AUTOSAR XML (schema 4-0-3)
package /AUTOSAR_Dcm/ImplementationDataTypes
  42 x impl type:
    DataArrayType_SystemSupplierECUHardwareVersionNumber: category=ARRAY
      element DataArrayType: array-size=4, array-size-semantics=FIXED-SIZE, implementation-data-type=uint8
    Dcm_EcuStartModeType: category=VALUE, base-type=uint8, compu {0x00=DCM_COLD_START, 0x01=DCM_WARM_START}, range raw 0x00..0x01
    DataArrayType_VINDataIdentifier: category=ARRAY
      element DataArrayType: array-size=17, array-size-semantics=FIXED-SIZE, implementation-data-type=uint8
    Dcm_ProtocolType:
      category=VALUE
      base-type=uint8
      compu {0x00=DCM_OBD_ON_CAN, 0x01=DCM_OBD_ON_FLEXRAY, 0x02=DCM_OBD_ON_IP, 0x03=DCM_UDS_ON_CAN, 0x04=DCM_UDS_ON_FLEXRAY, 0x05=DCM_UDS_ON_IP, 0x06=DCM_ROE_ON_CAN, 0x07=DCM_ROE_ON_FLEXRAY, 0x08=DCM_ROE_ON_IP, 0x09=DCM_PERIODICTRANS_ON_CAN, 0x0A=DCM_PERIODICTRANS_ON_FLEXRAY, 0x0B=DCM_PERIODICTRANS_ON_IP, 0x0C=DCM_NO_ACTIVE_PROTOCOL, 0xF0=DCM_SUPPLIER_1, 0xF1=DCM_SUPPLIER_2, 0xF2=DCM_SUPPLIER_3, 0xF3=DCM_SUPPLIER_4, 0xF4=DCM_SUPPLIER_5, 0xF5=DCM_SUPPLIER_6, 0xF6=DCM_SUPPLIER_7, 0xF7=DCM_SUPPLIER_8, 0xF8=DCM_SUPPLIER_9, 0xF9=DCM_SUPPLIER_10, 0xFA=DCM_SUPPLIER_11, 0xFB=DCM_SUPPLIER_12, 0xFC=DCM_SUPPLIER_13, 0xFD=DCM_SUPPLIER_14, 0xFE=DCM_SUPPLIER_15}
      range raw 0x00..0xFE
    Dcm_OpStatusType: category=VALUE, base-type=uint8, compu {0x00=DCM_INITIAL, 0x01=DCM_PENDING, 0x02=DCM_CANCEL, 0x03=DCM_FORCE_RCRRP_OK}, range raw 0x00..0x03
    Dcm_SecLevelType: category=VALUE, base-type=uint8, compu {0x00=DCM_SEC_LEV_LOCKED, 0x01=DCM_SEC_LEV_L1, 0x09=DCM_SEC_LEV_L9, 0x21=DCM_SEC_LEV_L21, 0xFF=DCM_SEC_LEV_ALL}, range raw 0x00..0xFF
    Dcm_MsgItemType: category=VALUE, base-type=uint8, range raw 0..255
    Dcm_ReturnReadMemoryType: category=VALUE, base-type=uint8, compu {0x02=DCM_READ_FAILED, 0x03=DCM_READ_FORCE_RCRRP, 0x00=DCM_READ_OK, 0x01=DCM_READ_PENDING}, range raw 0x00..0x03
    RequestDataOutType_RID_0200h_CalibrationActuator_routineStatus_ResOutSignal: category=VALUE, base-type=uint8, range raw 0..255
    StartDataOutType_RID_0200h_CalibrationActuator_routineStatus_StartOutSignal: category=VALUE, base-type=uint8, range raw 0..255
    DataArrayType_VehicleManufacturerECUSoftwareVersionNumber: category=ARRAY
      element DataArrayType: array-size=17, array-size-semantics=FIXED-SIZE, implementation-data-type=uint8
    Dcm_StatusType: category=VALUE, base-type=uint8, compu {0x00=DCM_E_OK, 0x08=DCM_E_REQUEST_NOT_ACCEPTED, 0x05=DCM_E_PROTOCOL_NOT_ALLOWED, 0x06=DCM_E_ROE_NOT_ACCEPTED, 0x07=DCM_E_PERIODICID_NOT_ACCEPTED, 0x11=DCM_E_COMPARE_KEY_FAILED}, range raw 0x00..0x11
    Dcm_ReturnWriteMemoryType: category=VALUE, base-type=uint8, compu {0x02=DCM_WRITE_FAILED, 0x03=DCM_WRITE_FORCE_RCRRP, 0x00=DCM_WRITE_OK, 0x01=DCM_WRITE_PENDING}, range raw 0x00..0x03
    SeedArrayType_L9: category=ARRAY
      element SeedArrayType: array-size=8, array-size-semantics=FIXED-SIZE, implementation-data-type=uint8
    DataArrayType_ECT: category=ARRAY
      element DataArrayType: array-size=1, array-size-semantics=FIXED-SIZE, implementation-data-type=uint8
    DTRStatusType: category=VALUE, base-type=uint8, range raw 0..255
    RequestDataArray: category=ARRAY
      element RequestDataArray: array-size=620, array-size-semantics=FIXED-SIZE, implementation-data-type=uint8
    DcmDspDidRangeArrayType_DIDs_0100h_0110h: category=ARRAY
      element DcmDspDidRangeArrayType: array-size=30, array-size-semantics=FIXED-SIZE, implementation-data-type=uint8
    Dcm_ProgConditionsType: category=STRUCTURE
      8 x element, all with category=TYPE_REFERENCE:
        TesterSourceAddr: implementation-data-type=uint16
        ProtocolId: implementation-data-type=uint8
        Sid: implementation-data-type=uint8
        SubFncId: implementation-data-type=uint8
        ReprogramingRequest: implementation-data-type=boolean
        ApplUpdated: implementation-data-type=boolean
        ResponseRequired: implementation-data-type=boolean
        SecLvInfo: implementation-data-type=uint8
    DataArrayType_VehicleSpeed: category=ARRAY
      element DataArrayType: array-size=1, array-size-semantics=FIXED-SIZE, implementation-data-type=uint8
    KeyArrayType_L1: category=ARRAY
      element KeyArrayType: array-size=4, array-size-semantics=FIXED-SIZE, implementation-data-type=uint8
    DataArrayType_BatVolt: category=ARRAY
      element DataArrayType: array-size=1, array-size-semantics=FIXED-SIZE, implementation-data-type=uint8
    Dcm_CertInfoType: category=STRUCTURE
      element authorization: implementation-data-type=Dcm_CertAuthorizationInfoType
      element expirationDate: implementation-data-type=Dcm_CertExpirationDateInfoType
    Dcm_MsgLenType: category=VALUE, base-type=uint32, range raw 0..4294967295
    DataArrayType_RPM: category=ARRAY
      element DataArrayType: array-size=2, array-size-semantics=FIXED-SIZE, implementation-data-type=uint8
    StopDataOutType_RID_0200h_CalibrationActuator_DcmDspRoutineStopOutSignal0: category=VALUE, base-type=uint8, range raw 0..255
    SeedArrayType_L1: category=ARRAY
      element SeedArrayType: array-size=4, array-size-semantics=FIXED-SIZE, implementation-data-type=uint8
    ScalingInfoArrayType_VINDataIdentifier: category=ARRAY
      element ScalingInfoArrayType: array-size=2, array-size-semantics=FIXED-SIZE, implementation-data-type=uint8
    Dcm_NegativeResponseCodeType:
      category=VALUE
      base-type=uint8
      compu {0x00=DCM_E_POSITIVERESPONSE, 0x10=DCM_E_GENERALREJECT, 0x11=DCM_E_SERVICENOTSUPPORTED, 0x12=DCM_E_SUBFUNCTIONNOTSUPPORTED, 0x13=DCM_E_INCORRECTMESSAGELENGTHORINVALIDFORMAT, 0x14=DCM_E_RESPONSETOOLONG, 0x21=DCM_E_BUSYREPEATREQUEST, 0x22=DCM_E_CONDITIONSNOTCORRECT, 0x24=DCM_E_REQUESTSEQUENCEERROR, 0x25=DCM_E_NORESPONSEFROMSUBNETCOMPONENT, 0x26=DCM_E_FAILUREPREVENTSEXECUTIONOFREQUESTEDACTION, 0x31=DCM_E_REQUESTOUTOFRANGE, 0x33=DCM_E_SECURITYACCESSDENIED, 0x35=DCM_E_INVALIDKEY, 0x36=DCM_E_EXCEEDNUMBEROFATTEMPTS, 0x37=DCM_E_REQUIREDTIMEDELAYNOTEXPIRED, 0x70=DCM_E_UPLOADDOWNLOADNOTACCEPTED, 0x71=DCM_E_TRANSFERDATASUSPENDED, 0x72=DCM_E_GENERALPROGRAMMINGFAILURE, 0x73=DCM_E_WRONGBLOCKSEQUENCECOUNTER, 0x7E=DCM_E_SUBFUNCTIONNOTSUPPORTEDINACTIVESESSION, 0x7F=DCM_E_SERVICENOTSUPPORTEDINACTIVESESSION, 0x81=DCM_E_RPMTOOHIGH, 0x82=DCM_E_RPMTOOLOW, 0x83=DCM_E_ENGINEISRUNNING, 0x84=DCM_E_ENGINEISNOTRUNNING, 0x85=DCM_E_ENGINERUNTIMETOOLOW, 0x86=DCM_E_TEMPERATURETOOHIGH, 0x87=DCM_E_TEMPERATURETOOLOW, 0x88=DCM_E_VEHICLESPEEDTOOHIGH, 0x89=DCM_E_VEHICLESPEEDTOOLOW, 0x8A=DCM_E_THROTTLE_PEDALTOOHIGH, 0x8B=DCM_E_THROTTLE_PEDALTOOLOW, 0x8C=DCM_E_TRANSMISSIONRANGENOTINNEUTRAL, 0x8D=DCM_E_TRANSMISSIONRANGENOTINGEAR, 0x8F=DCM_E_BRAKESWITCH_NOTCLOSED, 0x90=DCM_E_SHIFTERLEVERNOTINPARK, 0x91=DCM_E_TORQUECONVERTERCLUTCHLOCKED, 0x92=DCM_E_VOLTAGETOOHIGH, 0x93=DCM_E_VOLTAGETOOLOW, 0xF0=DCM_E_VMSCNC_0, 0xF1=DCM_E_VMSCNC_1, 0xF2=DCM_E_VMSCNC_2, 0xF3=DCM_E_VMSCNC_3, 0xF4=DCM_E_VMSCNC_4, 0xF5=DCM_E_VMSCNC_5, 0xF6=DCM_E_VMSCNC_6, 0xF7=DCM_E_VMSCNC_7, 0xF8=DCM_E_VMSCNC_8, 0xF9=DCM_E_VMSCNC_9, 0xFA=DCM_E_VMSCNC_A, 0xFB=DCM_E_VMSCNC_B, 0xFC=DCM_E_VMSCNC_C, 0xFD=DCM_E_VMSCNC_D, 0xFE=DCM_E_VMSCNC_E}
      range raw 0x00..0xFF
    DataArrayType_ActuatorControl: category=ARRAY
      element DataArrayType: array-size=1, array-size-semantics=FIXED-SIZE, implementation-data-type=uint8
    DataArrayType_SystemSupplierECUSoftwareNumber: category=ARRAY
      element DataArrayType: array-size=4, array-size-semantics=FIXED-SIZE, implementation-data-type=uint8
    KeyArrayType_L9: category=ARRAY
      element KeyArrayType: array-size=8, array-size-semantics=FIXED-SIZE, implementation-data-type=uint8
    Dcm_ConfirmationStatusType: category=VALUE, base-type=uint8, compu {0x00=DCM_RES_POS_OK, 0x01=DCM_RES_POS_NOT_OK, 0x02=DCM_RES_NEG_OK, 0x03=DCM_RES_NEG_NOT_OK}, range raw 0x00..0x03
    Dcm_IdContextType: category=VALUE, base-type=uint8, range raw 0..255
    Dcm_CertExpirationDateInfoType: category=ARRAY
      element expirationDate: array-size=3, array-size-semantics=FIXED-SIZE, implementation-data-type=uint8
    StartDataInType_RID_0200h_CalibrationActuator_routineControlOption_StartInSignal: category=VALUE, base-type=uint8, range raw 0..255
    Dcm_CertAuthorizationInfoType: category=ARRAY
      element authorization: array-size=4, array-size-semantics=FIXED-SIZE, implementation-data-type=uint8
    Dcm_RoeStateType: category=VALUE, base-type=uint8, compu {0x00=DCM_ROE_ACTIVE, 0x01=DCM_ROE_UNACTIVE}, range raw 0x00..0x01
    Dcm_SesCtrlType: category=VALUE, base-type=uint8, compu {0x01=DCM_DEFAULT_SESSION, 0x02=DCM_PROGRAMMING_SESSION, 0x03=DCM_EXTENDED_DIAGNOSTIC_SESSION, 0x04=DCM_SAFETY_SYSTEM_DIAGNOSTIC_SESSION, 0x10=DCM_EXTENDED_DIAGNOSTIC_MODE_10H, 0x05=DCM_ECU_PROGRAMMING_MODE_05H, 0x50=DCM_QUIESCENT_CURRENT_DIAGNOSTIC_MODE_START, 0x51=DCM_SLEEP_MODE_START_REQUEST, 0xFF=DCM_ALL_SESSION_LEVEL}, range raw 0x01..0xFF
    StopDataInType_RID_0200h_CalibrationActuator_DcmDspRoutineStopInSignal0: category=VALUE, base-type=uint8, range raw 0..255
    Dcm_CommunicationModeType:
      category=VALUE
      base-type=uint8
      compu {0x00=DCM_ENABLE_RX_TX_NORM, 0x01=DCM_ENABLE_RX_DISABLE_TX_NORM, 0x02=DCM_DISABLE_RX_ENABLE_TX_NORM, 0x03=DCM_DISABLE_RX_TX_NORMAL, 0x04=DCM_ENABLE_RX_TX_NM, 0x05=DCM_ENABLE_RX_DISABLE_TX_NM, 0x06=DCM_DISABLE_RX_ENABLE_TX_NM, 0x07=DCM_DISABLE_RX_TX_NM, 0x08=DCM_ENABLE_RX_TX_NORM_NM, 0x09=DCM_ENABLE_RX_DISABLE_TX_NORM_NM, 0x0A=DCM_DISABLE_RX_ENABLE_TX_NORM_NM, 0x0B=DCM_DISABLE_RX_TX_NORM_NM, 0x03=DCM_DISABLE_RX_TX_NORM}
      range raw 0x00..0x0B
    ScalingInfoArrayType_VehicleSpeed: category=ARRAY
      element ScalingInfoArrayType: array-size=9, array-size-semantics=FIXED-SIZE, implementation-data-type=uint8
package /AUTOSAR_Dcm/ClientServerInterfaces
  16 x client server interface, all with is-service=true:
    DataServices_SystemSupplierECUSoftwareNumber
      operation ConditionCheckRead: possible-error=DataServices_SystemSupplierECUSoftwareNumber/E_NOT_OK
        arg ErrorCode: type=Dcm_NegativeResponseCodeType, direction=OUT
      operation ReadData: possible-error=DataServices_SystemSupplierECUSoftwareNumber/E_NOT_OK
        arg Data: type=DataArrayType_SystemSupplierECUSoftwareNumber, direction=OUT
      error E_NOT_OK: error-code=1
      error DCM_E_PENDING: error-code=10
    DataServices_VINDataIdentifier
      4 x operation, all with possible-error=DataServices_VINDataIdentifier/E_NOT_OK:
        WriteData
          arg Data: type=DataArrayType_VINDataIdentifier, direction=IN
          arg ErrorCode: type=Dcm_NegativeResponseCodeType, direction=OUT
        ReadData
          arg Data: type=DataArrayType_VINDataIdentifier, direction=OUT
        ConditionCheckRead
          arg ErrorCode: type=Dcm_NegativeResponseCodeType, direction=OUT
        GetScalingInformation
          arg ScalingInfo: type=ScalingInfoArrayType_VINDataIdentifier, direction=OUT
          arg ErrorCode: type=Dcm_NegativeResponseCodeType, direction=OUT
      error DCM_E_PENDING: error-code=10
      error E_NOT_OK: error-code=1
    DCMServices
      5 x operation, all with possible-error=DCMServices/E_NOT_OK:
        GetSecurityLevel
          arg SecLevel: type=Dcm_SecLevelType, direction=OUT
        GetActiveProtocol
          arg ActiveProtocol: type=Dcm_ProtocolType, direction=OUT
        GetSesCtrlType
          arg SesCtrlType: type=Dcm_SesCtrlType, direction=OUT
        ResetToDefaultSession
        GetCertificationInfo
          arg CertInfo: type=Dcm_CertInfoType, direction=OUT
      error E_NOT_OK: error-code=1
    DataServices_ActuatorControl
      7 x operation, all with possible-error=DataServices_ActuatorControl/E_NOT_OK:
        FreezeCurrentState
          arg ErrorCode: type=Dcm_NegativeResponseCodeType, direction=OUT
        ResetToDefault
          arg ErrorCode: type=Dcm_NegativeResponseCodeType, direction=OUT
        ShortTermAdjustment
          arg ControlStateInfo: type=DataArrayType_ActuatorControl, direction=IN
          arg ErrorCode: type=Dcm_NegativeResponseCodeType, direction=OUT
        ReturnControlToECU
          arg ErrorCode: type=Dcm_NegativeResponseCodeType, direction=OUT
        ConditionCheckRead
          arg ErrorCode: type=Dcm_NegativeResponseCodeType, direction=OUT
        ReadData
          arg Data: type=DataArrayType_ActuatorControl, direction=OUT
        WriteData
          arg Data: type=DataArrayType_ActuatorControl, direction=IN
          arg ErrorCode: type=Dcm_NegativeResponseCodeType, direction=OUT
      error E_NOT_OK: error-code=1
      error DCM_E_PENDING: error-code=10
    DataServices_ECT
      operation WriteData: possible-error=DataServices_ECT/E_NOT_OK
        arg Data: type=DataArrayType_ECT, direction=IN
        arg ErrorCode: type=Dcm_NegativeResponseCodeType, direction=OUT
      operation ReadData: possible-error=DataServices_ECT/E_NOT_OK
        arg Data: type=DataArrayType_ECT, direction=OUT
      operation ConditionCheckRead: possible-error=DataServices_ECT/E_NOT_OK
        arg ErrorCode: type=Dcm_NegativeResponseCodeType, direction=OUT
      error E_NOT_OK: error-code=1
      error DCM_E_PENDING: error-code=10
    CallbackDCMRequestServices
      operation StopProtocol: possible-error=CallbackDCMRequestServices/E_NOT_OK
        arg ProtocolID: type=Dcm_ProtocolType, direction=IN
      operation StartProtocol: possible-error=[E_PROTOCOL_NOT_ALLOWED, CallbackDCMRequestServices/E_NOT_OK]
        arg ProtocolID: type=Dcm_ProtocolType, direction=IN
      error E_PROTOCOL_NOT_ALLOWED: error-code=5
      error E_NOT_OK: error-code=1
    DataServices_RPM
      6 x operation, all with possible-error=DataServices_RPM/E_NOT_OK:
        FreezeCurrentState
          arg ErrorCode: type=Dcm_NegativeResponseCodeType, direction=OUT
        ShortTermAdjustment
          arg ControlStateInfo: type=DataArrayType_RPM, direction=IN
          arg ErrorCode: type=Dcm_NegativeResponseCodeType, direction=OUT
        ReturnControlToECU
          arg ErrorCode: type=Dcm_NegativeResponseCodeType, direction=OUT
        ConditionCheckRead
          arg ErrorCode: type=Dcm_NegativeResponseCodeType, direction=OUT
        ReadData
          arg Data: type=DataArrayType_RPM, direction=OUT
        WriteData
          arg Data: type=DataArrayType_RPM, direction=IN
          arg ErrorCode: type=Dcm_NegativeResponseCodeType, direction=OUT
      error DCM_E_PENDING: error-code=10
      error E_NOT_OK: error-code=1
    SecurityAccess_L9
      operation CompareKey: possible-error=[SecurityAccess_L9/DCM_E_COMPARE_KEY_FAILED, SecurityAccess_L9/E_NOT_OK, SecurityAccess_L9/DCM_E_PENDING]
        arg Key: type=KeyArrayType_L9, direction=IN
        arg OpStatus: type=Dcm_OpStatusType, direction=IN
      operation GetSeed: possible-error=[SecurityAccess_L9/E_NOT_OK, SecurityAccess_L9/DCM_E_PENDING]
        arg OpStatus: type=Dcm_OpStatusType, direction=IN
        arg Seed: type=SeedArrayType_L9, direction=OUT
        arg ErrorCode: type=Dcm_NegativeResponseCodeType, direction=OUT
      error DCM_E_PENDING: error-code=10
      error E_NOT_OK: error-code=1
      error DCM_E_COMPARE_KEY_FAILED: error-code=11
    ServiceRequestNotification
      operation Confirmation: possible-error=ServiceRequestNotification/E_NOT_OK
        4 x arg, all with direction=IN:
          SID: type=uint8
          ReqType: type=uint8
          SourceAddress: type=uint16
          ConfirmationStatus: type=Dcm_ConfirmationStatusType
      operation Indication: possible-error=[ServiceRequestNotification/E_NOT_OK, E_REQUEST_NOT_ACCEPTED]
        6 x arg:
          SID: type=uint8, direction=IN
          RequestData: type=RequestDataArray, direction=IN
          DataSize: type=uint16, direction=IN
          ReqType: type=uint8, direction=IN
          SourceAddress: type=uint16, direction=IN
          ErrorCode: type=Dcm_NegativeResponseCodeType, direction=OUT
      error E_NOT_OK: error-code=1
      error E_REQUEST_NOT_ACCEPTED: error-code=8
    DataServices_VehicleSpeed
      operation GetScalingInformation: possible-error=DataServices_VehicleSpeed/E_NOT_OK
        arg ScalingInfo: type=ScalingInfoArrayType_VehicleSpeed, direction=OUT
        arg ErrorCode: type=Dcm_NegativeResponseCodeType, direction=OUT
      operation ReadData: possible-error=DataServices_VehicleSpeed/E_NOT_OK
        arg Data: type=DataArrayType_VehicleSpeed, direction=OUT
      operation ConditionCheckRead: possible-error=DataServices_VehicleSpeed/E_NOT_OK
        arg ErrorCode: type=Dcm_NegativeResponseCodeType, direction=OUT
      error DCM_E_PENDING: error-code=10
      error E_NOT_OK: error-code=1
    DataServices_DIDRange_DIDs_0100h_0110h
      operation IsDidAvailable: possible-error=[DataServices_DIDRange_DIDs_0100h_0110h/DCM_E_PENDING, DataServices_DIDRange_DIDs_0100h_0110h/E_NOT_OK]
        arg DID: type=uint16, direction=IN
        arg supported: type=uint8, direction=OUT
      operation WriteDidData: possible-error=[DataServices_DIDRange_DIDs_0100h_0110h/DCM_E_PENDING, DataServices_DIDRange_DIDs_0100h_0110h/E_NOT_OK]
        5 x arg:
          DID: type=uint16, direction=IN
          Data: type=DcmDspDidRangeArrayType_DIDs_0100h_0110h, direction=IN
          OpStatus: type=Dcm_OpStatusType, direction=IN
          DataLength: type=uint16, direction=IN
          ErrorCode: type=Dcm_NegativeResponseCodeType, direction=OUT
      operation ReadDidData: possible-error=[DataServices_DIDRange_DIDs_0100h_0110h/DCM_E_PENDING, DataServices_DIDRange_DIDs_0100h_0110h/E_NOT_OK]
        5 x arg:
          DID: type=uint16, direction=IN
          Data: type=DcmDspDidRangeArrayType_DIDs_0100h_0110h, direction=OUT
          OpStatus: type=Dcm_OpStatusType, direction=IN
          DataLength: type=uint16, direction=OUT
          ErrorCode: type=Dcm_NegativeResponseCodeType, direction=OUT
      error E_NOT_OK: error-code=1
      error DCM_E_PENDING: error-code=10
    DataServices_BatVolt
      operation WriteData: possible-error=DataServices_BatVolt/E_NOT_OK
        arg Data: type=DataArrayType_BatVolt, direction=IN
        arg ErrorCode: type=Dcm_NegativeResponseCodeType, direction=OUT
      operation ReadData: possible-error=DataServices_BatVolt/E_NOT_OK
        arg Data: type=DataArrayType_BatVolt, direction=OUT
      operation ConditionCheckRead: possible-error=DataServices_BatVolt/E_NOT_OK
        arg ErrorCode: type=Dcm_NegativeResponseCodeType, direction=OUT
      error DCM_E_PENDING: error-code=10
      error E_NOT_OK: error-code=1
    SecurityAccess_L1
      operation CompareKey: possible-error=[SecurityAccess_L1/E_NOT_OK, SecurityAccess_L1/DCM_E_PENDING, SecurityAccess_L1/DCM_E_COMPARE_KEY_FAILED]
        arg Key: type=KeyArrayType_L1, direction=IN
        arg OpStatus: type=Dcm_OpStatusType, direction=IN
      operation GetSeed: possible-error=[SecurityAccess_L1/E_NOT_OK, SecurityAccess_L1/DCM_E_PENDING]
        arg OpStatus: type=Dcm_OpStatusType, direction=IN
        arg Seed: type=SeedArrayType_L1, direction=OUT
        arg ErrorCode: type=Dcm_NegativeResponseCodeType, direction=OUT
      error DCM_E_COMPARE_KEY_FAILED: error-code=11
      error DCM_E_PENDING: error-code=10
      error E_NOT_OK: error-code=1
    RoutineServices_RID_0200h_CalibrationActuator
      operation Start: possible-error=[DCM_E_FORCE_RCRRP, RoutineServices_RID_0200h_CalibrationActuator/E_NOT_OK, RoutineServices_RID_0200h_CalibrationActuator/DCM_E_PENDING]
        4 x arg:
          DataIn_routineControlOption_StartInSignal: type=StartDataInType_RID_0200h_CalibrationActuator_routineControlOption_StartInSignal, direction=IN
          OpStatus: type=Dcm_OpStatusType, direction=IN
          DataOut_routineStatus_StartOutSignal: type=StartDataOutType_RID_0200h_CalibrationActuator_routineStatus_StartOutSignal, direction=OUT
          ErrorCode: type=Dcm_NegativeResponseCodeType, direction=OUT
      operation RequestResults: possible-error=[DCM_E_FORCE_RCRRP, RoutineServices_RID_0200h_CalibrationActuator/E_NOT_OK, RoutineServices_RID_0200h_CalibrationActuator/DCM_E_PENDING]
        arg OpStatus: type=Dcm_OpStatusType, direction=IN
        arg DataOut_routineStatus_ResOutSignal: type=RequestDataOutType_RID_0200h_CalibrationActuator_routineStatus_ResOutSignal, direction=OUT
        arg ErrorCode: type=Dcm_NegativeResponseCodeType, direction=OUT
      operation Stop: possible-error=[DCM_E_FORCE_RCRRP, RoutineServices_RID_0200h_CalibrationActuator/E_NOT_OK, RoutineServices_RID_0200h_CalibrationActuator/DCM_E_PENDING]
        4 x arg:
          DataIn_DcmDspRoutineStopInSignal0: type=StopDataInType_RID_0200h_CalibrationActuator_DcmDspRoutineStopInSignal0, direction=IN
          OpStatus: type=Dcm_OpStatusType, direction=IN
          DataOut_DcmDspRoutineStopOutSignal0: type=StopDataOutType_RID_0200h_CalibrationActuator_DcmDspRoutineStopOutSignal0, direction=OUT
          ErrorCode: type=Dcm_NegativeResponseCodeType, direction=OUT
      error DCM_E_FORCE_RCRRP: error-code=12
      error DCM_E_PENDING: error-code=10
      error E_NOT_OK: error-code=1
    DataServices_SystemSupplierECUHardwareVersionNumber
      operation ReadData: possible-error=DataServices_SystemSupplierECUHardwareVersionNumber/E_NOT_OK
        arg Data: type=DataArrayType_SystemSupplierECUHardwareVersionNumber, direction=OUT
      operation ConditionCheckRead: possible-error=DataServices_SystemSupplierECUHardwareVersionNumber/E_NOT_OK
        arg ErrorCode: type=Dcm_NegativeResponseCodeType, direction=OUT
      error DCM_E_PENDING: error-code=10
      error E_NOT_OK: error-code=1
    DataServices_VehicleManufacturerECUSoftwareVersionNumber
      operation ReadData: possible-error=DataServices_VehicleManufacturerECUSoftwareVersionNumber/E_NOT_OK
        arg Data: type=DataArrayType_VehicleManufacturerECUSoftwareVersionNumber, direction=OUT
      operation ConditionCheckRead: possible-error=DataServices_VehicleManufacturerECUSoftwareVersionNumber/E_NOT_OK
        arg ErrorCode: type=Dcm_NegativeResponseCodeType, direction=OUT
      error E_NOT_OK: error-code=1
      error DCM_E_PENDING: error-code=10
package /AUTOSAR_Dcm/ServiceSwComponentTypes
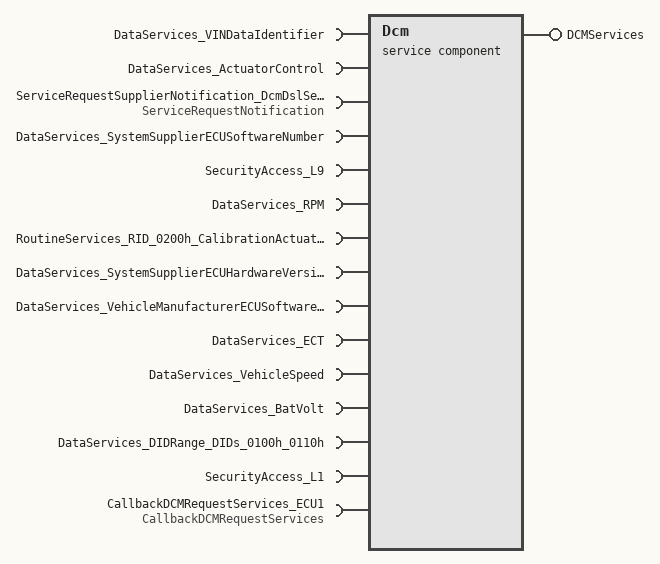
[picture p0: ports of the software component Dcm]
  service sw component type Dcm
    provide port DCMServices: provided-interface=DCMServices
      provided-com-specs:
        operation=GetSecurityLevel, queue-length=1
        operation=GetActiveProtocol, queue-length=1
        operation=GetSesCtrlType, queue-length=1
        operation=ResetToDefaultSession, queue-length=1
        operation=GetCertificationInfo, queue-length=1
    15 x require port:
      DataServices_VINDataIdentifier: required-interface=DataServices_VINDataIdentifier
        required-com-specs:
          DataServices_VINDataIdentifier/WriteData
          DataServices_VINDataIdentifier/ReadData
          DataServices_VINDataIdentifier/ConditionCheckRead
          DataServices_VINDataIdentifier/GetScalingInformation
      DataServices_ActuatorControl: required-interface=DataServices_ActuatorControl
        required-com-specs:
          DataServices_ActuatorControl/FreezeCurrentState
          ResetToDefault
          DataServices_ActuatorControl/ShortTermAdjustment
          DataServices_ActuatorControl/ReturnControlToECU
          DataServices_ActuatorControl/ConditionCheckRead
          DataServices_ActuatorControl/ReadData
          DataServices_ActuatorControl/WriteData
      ServiceRequestSupplierNotification_DcmDslServiceRequestSupplierNotification0: required-com-specs=[Confirmation, Indication], required-interface=ServiceRequestNotification
      DataServices_SystemSupplierECUSoftwareNumber: required-interface=DataServices_SystemSupplierECUSoftwareNumber
        required-com-specs:
          DataServices_SystemSupplierECUSoftwareNumber/ConditionCheckRead
          DataServices_SystemSupplierECUSoftwareNumber/ReadData
      SecurityAccess_L9: required-com-specs=[SecurityAccess_L9/CompareKey, SecurityAccess_L9/GetSeed], required-interface=SecurityAccess_L9
      DataServices_RPM: required-interface=DataServices_RPM
        required-com-specs:
          DataServices_RPM/FreezeCurrentState
          DataServices_RPM/ShortTermAdjustment
          DataServices_RPM/ReturnControlToECU
          DataServices_RPM/ConditionCheckRead
          DataServices_RPM/ReadData
          DataServices_RPM/WriteData
      RoutineServices_RID_0200h_CalibrationActuator: required-com-specs=[Start, RequestResults, Stop], required-interface=RoutineServices_RID_0200h_CalibrationActuator
      DataServices_SystemSupplierECUHardwareVersionNumber: required-interface=DataServices_SystemSupplierECUHardwareVersionNumber
        required-com-specs:
          DataServices_SystemSupplierECUHardwareVersionNumber/ReadData
          DataServices_SystemSupplierECUHardwareVersionNumber/ConditionCheckRead
      DataServices_VehicleManufacturerECUSoftwareVersionNumber: required-interface=DataServices_VehicleManufacturerECUSoftwareVersionNumber
        required-com-specs:
          DataServices_VehicleManufacturerECUSoftwareVersionNumber/ReadData
          DataServices_VehicleManufacturerECUSoftwareVersionNumber/ConditionCheckRead
      DataServices_ECT: required-com-specs=[DataServices_ECT/WriteData, DataServices_ECT/ReadData, DataServices_ECT/ConditionCheckRead], required-interface=DataServices_ECT
      DataServices_VehicleSpeed: required-interface=DataServices_VehicleSpeed
        required-com-specs:
          DataServices_VehicleSpeed/GetScalingInformation
          DataServices_VehicleSpeed/ReadData
          DataServices_VehicleSpeed/ConditionCheckRead
      DataServices_BatVolt: required-com-specs=[DataServices_BatVolt/WriteData, DataServices_BatVolt/ReadData, DataServices_BatVolt/ConditionCheckRead], required-interface=DataServices_BatVolt
      DataServices_DIDRange_DIDs_0100h_0110h: required-com-specs=[IsDidAvailable, WriteDidData, ReadDidData], required-interface=DataServices_DIDRange_DIDs_0100h_0110h
      SecurityAccess_L1: required-com-specs=[SecurityAccess_L1/CompareKey, SecurityAccess_L1/GetSeed], required-interface=SecurityAccess_L1
      CallbackDCMRequestServices_ECU1: required-com-specs=[StopProtocol, StartProtocol], required-interface=CallbackDCMRequestServices
    behavior DcmInternalBehavior: handle-termination-and-restart=NO-SUPPORT, included-data-type-set=data-type=[DataArrayType_SystemSupplierECUHardwareVersionNumber, Dcm_EcuStartModeType, DataArrayType_VINDataIdentifier, Dcm_ProtocolType, Dcm_OpStatusType, Dcm_SecLevelType, Dcm_MsgItemType, Dcm_ReturnReadMemoryType, RequestDataOutType_RID_0200h_CalibrationActuator_routineStatus_ResOutSignal, StartDataOutType_RID_0200h_CalibrationActuator_routineStatus_StartOutSignal, DataArrayType_VehicleManufacturerECUSoftwareVersionNumber, Dcm_StatusType, Dcm_ReturnWriteMemoryType, SeedArrayType_L9, DataArrayType_ECT, DTRStatusType, RequestDataArray, DcmDspDidRangeArrayType_DIDs_0100h_0110h, Dcm_ProgConditionsType, DataArrayType_VehicleSpeed, KeyArrayType_L1, DataArrayType_BatVolt, Dcm_CertInfoType, Dcm_MsgLenType, DataArrayType_RPM, StopDataOutType_RID_0200h_CalibrationActuator_DcmDspRoutineStopOutSignal0, SeedArrayType_L1, ScalingInfoArrayType_VINDataIdentifier, Dcm_NegativeResponseCodeType, DataArrayType_ActuatorControl, DataArrayType_SystemSupplierECUSoftwareNumber, KeyArrayType_L9, Dcm_ConfirmationStatusType, Dcm_IdContextType, Dcm_CertExpirationDateInfoType, StartDataInType_RID_0200h_CalibrationActuator_routineControlOption_StartInSignal, Dcm_CertAuthorizationInfoType, Dcm_RoeStateType, Dcm_SesCtrlType, StopDataInType_RID_0200h_CalibrationActuator_DcmDspRoutineStopInSignal0, Dcm_CommunicationModeType, ScalingInfoArrayType_VehicleSpeed]
      5 x operation invoked event:
        OIE_DCMServices_GetSecurityLevel: start-on-event=GetSecurityLevel, operation=DCMServices.GetSecurityLevel
        OIE_DCMServices_GetActiveProtocol: start-on-event=GetActiveProtocol, operation=DCMServices.GetActiveProtocol
        OIE_DCMServices_GetSesCtrlType: start-on-event=GetSesCtrlType, operation=DCMServices.GetSesCtrlType
        OIE_DCMServices_ResetToDefaultSession: start-on-event=ResetToDefaultSession, operation=DCMServices.ResetToDefaultSession
        OIE_DCMServices_GetCertificationInfo: start-on-event=GetCertificationInfo, operation=DCMServices.GetCertificationInfo
      6 x runnable, all with can-be-invoked-concurrently=true:
        GetSecurityLevel: symbol=Dcm_GetSecurityLevel
        GetActiveProtocol: symbol=Dcm_GetActiveProtocol
        GetSesCtrlType: symbol=Dcm_GetSesCtrlType
        ResetToDefaultSession: symbol=Dcm_ResetToDefaultSession
        GetCertificationInfo: symbol=Dcm_GetCertificationInfo
        MainFunction: symbol=Dcm_MainFunction
          46 x sync call, all with timeout=0:
            SSCP_DataServices_VINDataIdentifier_WriteData: operation=DataServices_VINDataIdentifier.WriteData
            SSCP_DataServices_VINDataIdentifier_ReadData: operation=DataServices_VINDataIdentifier.ReadData
            SSCP_DataServices_VINDataIdentifier_ConditionCheckRead: operation=DataServices_VINDataIdentifier.ConditionCheckRead
            SSCP_DataServices_VINDataIdentifier_GetScalingInformation: operation=DataServices_VINDataIdentifier.GetScalingInformation
            SSCP_DataServices_ActuatorControl_FreezeCurrentState: operation=DataServices_ActuatorControl.FreezeCurrentState
            SSCP_DataServices_ActuatorControl_ResetToDefault: operation=DataServices_ActuatorControl.ResetToDefault
            SSCP_DataServices_ActuatorControl_ShortTermAdjustment: operation=DataServices_ActuatorControl.ShortTermAdjustment
            SSCP_DataServices_ActuatorControl_ReturnControlToECU: operation=DataServices_ActuatorControl.ReturnControlToECU
            SSCP_DataServices_ActuatorControl_ConditionCheckRead: operation=DataServices_ActuatorControl.ConditionCheckRead
            SSCP_DataServices_ActuatorControl_ReadData: operation=DataServices_ActuatorControl.ReadData
            SSCP_DataServices_ActuatorControl_WriteData: operation=DataServices_ActuatorControl.WriteData
            SSCP_ServiceRequestSupplierNotification_DcmDslServiceRequestSupplierNotification0_Confirmation: operation=ServiceRequestSupplierNotification_DcmDslServiceRequestSupplierNotification0.Confirmation
            SSCP_ServiceRequestSupplierNotification_DcmDslServiceRequestSupplierNotification0_Indication: operation=ServiceRequestSupplierNotification_DcmDslServiceRequestSupplierNotification0.Indication
            SSCP_DataServices_SystemSupplierECUSoftwareNumber_ConditionCheckRead: operation=DataServices_SystemSupplierECUSoftwareNumber.ConditionCheckRead
            SSCP_DataServices_SystemSupplierECUSoftwareNumber_ReadData: operation=DataServices_SystemSupplierECUSoftwareNumber.ReadData
            SSCP_SecurityAccess_L9_CompareKey: operation=SecurityAccess_L9.CompareKey
            SSCP_SecurityAccess_L9_GetSeed: operation=SecurityAccess_L9.GetSeed
            SSCP_DataServices_RPM_FreezeCurrentState: operation=DataServices_RPM.FreezeCurrentState
            SSCP_DataServices_RPM_ShortTermAdjustment: operation=DataServices_RPM.ShortTermAdjustment
            SSCP_DataServices_RPM_ReturnControlToECU: operation=DataServices_RPM.ReturnControlToECU
            SSCP_DataServices_RPM_ConditionCheckRead: operation=DataServices_RPM.ConditionCheckRead
            SSCP_DataServices_RPM_ReadData: operation=DataServices_RPM.ReadData
            SSCP_DataServices_RPM_WriteData: operation=DataServices_RPM.WriteData
            SSCP_RoutineServices_RID_0200h_CalibrationActuator_Start: operation=RoutineServices_RID_0200h_CalibrationActuator.Start
            SSCP_RoutineServices_RID_0200h_CalibrationActuator_RequestResults: operation=RoutineServices_RID_0200h_CalibrationActuator.RequestResults
            SSCP_RoutineServices_RID_0200h_CalibrationActuator_Stop: operation=RoutineServices_RID_0200h_CalibrationActuator.Stop
            SSCP_DataServices_SystemSupplierECUHardwareVersionNumber_ReadData: operation=DataServices_SystemSupplierECUHardwareVersionNumber.ReadData
            SSCP_DataServices_SystemSupplierECUHardwareVersionNumber_ConditionCheckRead: operation=DataServices_SystemSupplierECUHardwareVersionNumber.ConditionCheckRead
            SSCP_DataServices_VehicleManufacturerECUSoftwareVersionNumber_ReadData: operation=DataServices_VehicleManufacturerECUSoftwareVersionNumber.ReadData
            SSCP_DataServices_VehicleManufacturerECUSoftwareVersionNumber_ConditionCheckRead: operation=DataServices_VehicleManufacturerECUSoftwareVersionNumber.ConditionCheckRead
            SSCP_DataServices_ECT_WriteData: operation=DataServices_ECT.WriteData
            SSCP_DataServices_ECT_ReadData: operation=DataServices_ECT.ReadData
            SSCP_DataServices_ECT_ConditionCheckRead: operation=DataServices_ECT.ConditionCheckRead
            SSCP_DataServices_VehicleSpeed_GetScalingInformation: operation=DataServices_VehicleSpeed.GetScalingInformation
            SSCP_DataServices_VehicleSpeed_ReadData: operation=DataServices_VehicleSpeed.ReadData
            SSCP_DataServices_VehicleSpeed_ConditionCheckRead: operation=DataServices_VehicleSpeed.ConditionCheckRead
            SSCP_DataServices_BatVolt_WriteData: operation=DataServices_BatVolt.WriteData
            SSCP_DataServices_BatVolt_ReadData: operation=DataServices_BatVolt.ReadData
            SSCP_DataServices_BatVolt_ConditionCheckRead: operation=DataServices_BatVolt.ConditionCheckRead
            SSCP_DataServices_DIDRange_DIDs_0100h_0110h_IsDidAvailable: operation=DataServices_DIDRange_DIDs_0100h_0110h.IsDidAvailable
            SSCP_DataServices_DIDRange_DIDs_0100h_0110h_WriteDidData: operation=DataServices_DIDRange_DIDs_0100h_0110h.WriteDidData
            SSCP_DataServices_DIDRange_DIDs_0100h_0110h_ReadDidData: operation=DataServices_DIDRange_DIDs_0100h_0110h.ReadDidData
            SSCP_SecurityAccess_L1_CompareKey: operation=SecurityAccess_L1.CompareKey
            SSCP_SecurityAccess_L1_GetSeed: operation=SecurityAccess_L1.GetSeed
            SSCP_CallbackDCMRequestServices_ECU1_StopProtocol: operation=CallbackDCMRequestServices_ECU1.StopProtocol
            SSCP_CallbackDCMRequestServices_ECU1_StartProtocol: operation=CallbackDCMRequestServices_ECU1.StartProtocol
  swc implementation Dcm_SwcImplementation: programming-language=C, sw-version=1.0.0.0, swc-bsw-mapping=SwcBswMapping_Dcm, vendor-id=0, behavior=DcmInternalBehavior
    code-descriptors:
      code CodeDescriptor: artifact-descriptors=autosar-engineering-object={short-label=Dcm_LibObjects, category=SWLIB, domain=AUTOSAR_DCM}
    resource consumption ResourceConsumption
  swc bsw mapping SwcBswMapping_Dcm: bsw-behavior=InternalBehavior_Dcm, swc-bsw-runnable-mapping{bsw-entity=BswSE_Dcm_MainFunction, swc-runnable=MainFunction}, swc-behavior=DcmInternalBehavior
